# Z20K14xM register map
Vendor: Zhixin Semiconductor; Series: Z20K14xM; File version: 0.1.0
CPU: CM4 r0p1, little endian, no MPU, FPU, 4 interrupt priority bits
Registers are 32-bit, read-write, reset 0x0 unless marked. A register's access mark holds for its fields unless they carry their own. Offsets are from the block's base; [hi:lo] are bit positions; {n}, {i} and the like mark numbered series.

## ADC1
Base 0x40027000
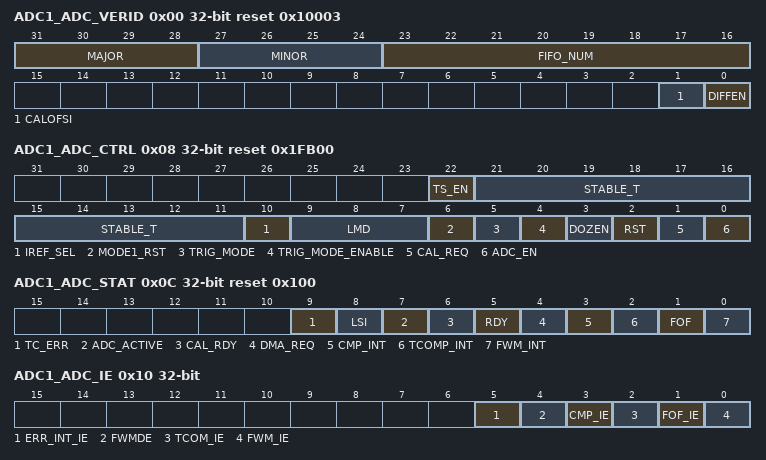
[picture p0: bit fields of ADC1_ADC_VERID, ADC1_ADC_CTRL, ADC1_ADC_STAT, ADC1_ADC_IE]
0x00 ADC1_ADC_VERID ro reset 0x10003 — ADC version ID Register(ADC_VERID)
  [31:28] MAJOR — Major Version Number
  [27:24] MINOR — Minor Version Number
  [23:16] FIFO_NUM — The number of FIFO
  [1] CALOFSI — Calibration Function Implemented
  [0] DIFFEN — Differential Supported
0x04 ADC1_ADC_PARAM ro reset 0x1000 — ADC PARAMETER Register(ADC_PARAM)
  [15:8] FIFO_SIZE — FIFO Depth field
0x08 ADC1_ADC_CTRL reset 0x1FB00 — ADC Control Register(ADC_CTRL)
  [22] TS_EN — temperature sensor enable
  [21:11] STABLE_T — adc stable time
  [10] IREF_SEL — iref source select
  [9:7] LMD — loop mode depth
  [6] MODE1_RST — mode1 loop reset bit
  [5] TRIG_MODE — Trigger mode
  [4] TRIG_MODE_ENABLE
  [3] DOZEN — Doze Enable
  [2] RST — Software Reset
  [1] CAL_REQ — Auto-Calibration Request
  [0] ADC_EN — ADC Enable
0x0C ADC1_ADC_STAT ro reset 0x100 — ADC STATUS Register(ADC_STAT)
  [9] TC_ERR — trigger confict err
  [8] LSI — loop state idle
  [7] ADC_ACTIVE
  [6] CAL_RDY — Calibration Ready
  [5] RDY — Result FIFO Ready Flag
  [4] DMA_REQ — DMA Request
  [3] CMP_INT — Compare Interrupt
  [2] TCOMP_INT — Complete Interrupt
  [1] FOF — Result FIFO Overflow Flag
  [0] FWM_INT — FIFO Watermark Interrupt
0x10 ADC1_ADC_IE — ADC Interrupt Enable Register(ADC_IE)
  [5] ERR_INT_IE — trigger confict err Interrupt Enable
  [4] FWMDE — FIFO Watermark DMA Enable
  [3] CMP_IE — Compare Interrupt Enable
  [2] TCOM_IE — Trigger Completion Interrupt Enable
  [1] FOF_IE — Result FIFO Overflow Interrupt Enable
  [0] FWM_IE — FIFO Watermark Interrupt Enable
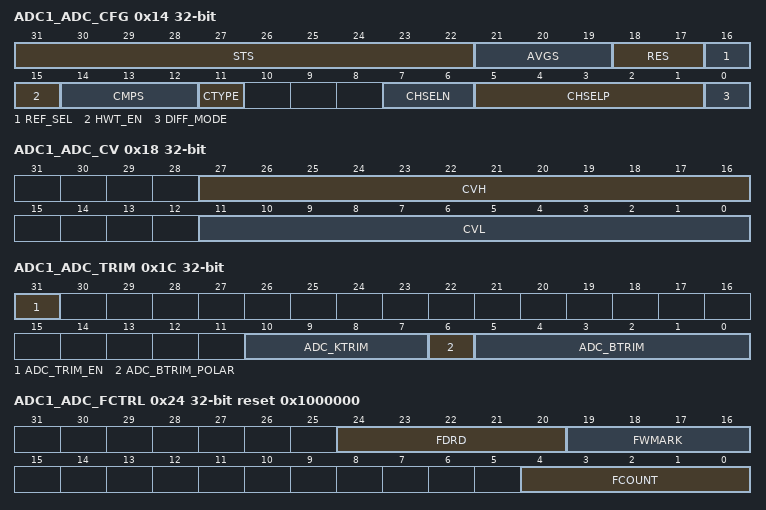
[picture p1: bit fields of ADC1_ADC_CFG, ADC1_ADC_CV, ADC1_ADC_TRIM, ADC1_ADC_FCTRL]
0x14 ADC1_ADC_CFG — ADC Configure information(ADC_CFG)
  [31:22] STS — Sample Time Select
  [21:19] AVGS — Hardware Average Select
  [18:17] RES — Resolution Select
  [16] REF_SEL — Reference Select
  [15] HWT_EN — HardWareTrigger Enable
  [14:12] CMPS — Compare Select
  [11] CTYPE — Conversion Type
  [7:6] CHSELN — Input Channel-N Select
  [5:1] CHSELP — Input Channel-P Select
  [0] DIFF_MODE — Differential Mode Select
0x18 ADC1_ADC_CV — ADC Compare Value Register(ADC_CV)
  [27:16] CVH — Compare Value High
  [11:0] CVL — Compare Value Low
0x1C ADC1_ADC_TRIM — ADC Trim Value Register(ADC_TRIM)
  [31] ADC_TRIM_EN — ADC Trim Write Enable
  [10:7] ADC_KTRIM — ADC KTRIM Value
  [6] ADC_BTRIM_POLAR — ADC BTRIM POLAR Value
  [5:0] ADC_BTRIM — ADC BTRIM Value
0x20 ADC1_ADC_DATA_RD ro — ADC Data Register(ADC_DATA_RD)
  [16:0] ADC_DATA_RD — conversion result
0x24 ADC1_ADC_FCTRL reset 0x1000000 — ADC FIFO Configuration Register(ADC_FCTRL)
  [24:20] FDRD — FIFO Depth Redefine
  [19:16] FWMARK — FIFO Watermark
  [4:0] FCOUNT — FIFO Counter
0x28 ADC1_ADC_SWTRIG — ADC SoftWareTrigger Register(ADC_SWTRIG)
  [0] ADC_SWTRIG — ADC SoftWare Trigger
0x2C ADC1_ADC_CAL_VAL ro — ADC Calibration Value(ADC_CAL_VAL)
  [12:0] ADC_CAL_VAL — ADC Calibration Value
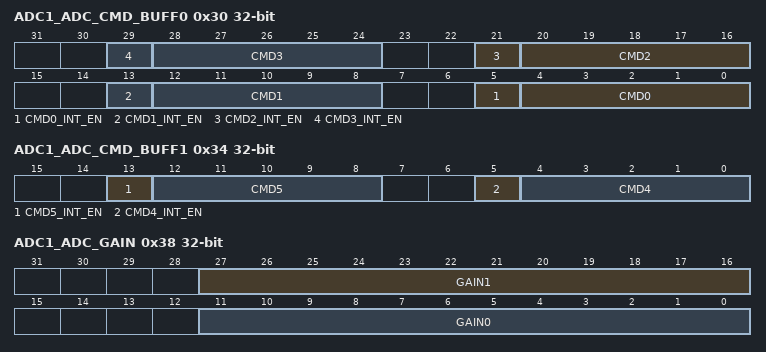
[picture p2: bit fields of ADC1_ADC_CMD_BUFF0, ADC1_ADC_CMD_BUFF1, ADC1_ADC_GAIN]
0x30 ADC1_ADC_CMD_BUFF0 — ADC Commond Buff Register0(ADC_CMD_BUFF0)
  [8n+5] CMD{n}_INT_EN (n=0..3) — cmd{n} complete int enable
  [8n+4:8n] CMD{n} (n=0..3) — cmd_buff{n}
0x34 ADC1_ADC_CMD_BUFF1 — ADC Command Buff Register1(ADC_CMD_BUFF1)
  [13] CMD5_INT_EN — cmd5 complete int enable
  [12:8] CMD5 — cmd_buff5
  [5] CMD4_INT_EN — cmd4 complete int enable
  [4:0] CMD4 — cmd_buff4
0x38 ADC1_ADC_GAIN — ADC gain trim register
  [27:16] GAIN1 — gain trim1
  [11:0] GAIN0 — gain trim0

## ADC0
Base 0x4003B000
Registers as ADC1 (with ADC1 read as ADC0).

## CRC
Base 0x40032000
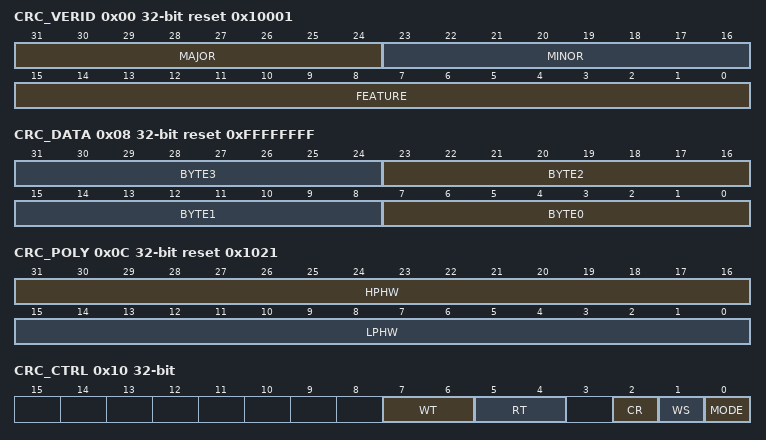
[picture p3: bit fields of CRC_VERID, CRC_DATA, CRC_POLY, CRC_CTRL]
0x00 CRC_VERID ro reset 0x10001 — CRC Version Number(CRC_VERID)
  [31:24] MAJOR — Major Version Number
  [23:16] MINOR — Minor Version Number
  [15:0] FEATURE — Module Identification Number
0x04 CRC_PARAM ro — CRC Parameter Register(CRC_PARAM)
0x08 CRC_DATA reset 0xFFFFFFFF — CRC Data register(CRC_DATA)
  [8n+7:8n] BYTE{n} (n=0..3) — CRC Data Byte{n}
0x0C CRC_POLY reset 0x1021 — CRC Polynomial register(CRC_POLY)
  [31:16] HPHW — High Polynominal Half-word
  [15:0] LPHW — Low Polynominal Half-word
0x10 CRC_CTRL — CRC Control register(CRC_CTRL)
  [7:6] WT — Write Type Of Transpose
  [5:4] RT — Read Type Of Transpose
  [2] CR — Complement Read
  [1] WS — Write seed
  [0] MODE — CRC mode
